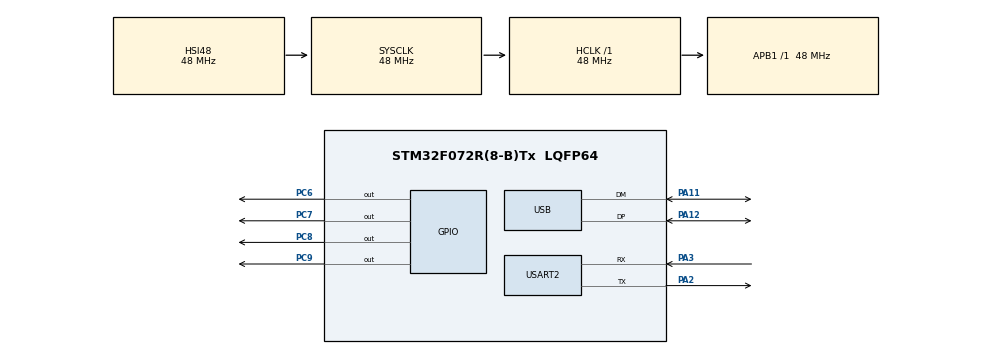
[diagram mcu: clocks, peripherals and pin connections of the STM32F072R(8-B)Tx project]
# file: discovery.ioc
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Dma.Request0=USART2_TX
Dma.USART2_TX.0.Direction=DMA_MEMORY_TO_PERIPH
Dma.USART2_TX.0.Instance=DMA1_Channel4
Dma.USART2_TX.0.MemDataAlignment=DMA_MDATAALIGN_BYTE
Dma.USART2_TX.0.MemInc=DMA_MINC_ENABLE
Dma.USART2_TX.0.Mode=DMA_NORMAL
Dma.USART2_TX.0.PeriphDataAlignment=DMA_PDATAALIGN_BYTE
Dma.USART2_TX.0.PeriphInc=DMA_PINC_DISABLE
Dma.USART2_TX.0.Priority=DMA_PRIORITY_LOW
Mcu.Family=STM32F0
Mcu.Name=STM32F072R(8-B)Tx
Mcu.Package=LQFP64
NVIC.DMA1_Channel4_5_6_7_IRQn=true\:0\:0\:false\:false\:true\:false
NVIC.TIM2_IRQn=true\:0\:0\:false\:false\:true\:true
NVIC.USB_IRQn=true\:0\:0\:false\:false\:true\:false
PA11.Mode=Device
PA11.Signal=USB_DM
PA12.Mode=Device
PA12.Signal=USB_DP
PA2.Mode=Asynchronous
PA2.Signal=USART2_TX
PA3.Mode=Asynchronous
PA3.Signal=USART2_RX
PC6.Signal=GPIO_Output
PC7.Signal=GPIO_Output
PC8.Signal=GPIO_Output
PC9.Signal=GPIO_Output
PF0-OSC_IN.Mode=HSE-External-Oscillator
PF0-OSC_IN.Signal=RCC_OSC_IN
PF1-OSC_OUT.Mode=HSE-External-Oscillator
PF1-OSC_OUT.Signal=RCC_OSC_OUT
ProjectManager.HeapSize=0x200
ProjectManager.StackSize=0x400
ProjectManager.TargetToolchain=MDK-ARM V5
RCC.AHBFreq_Value=48000000
RCC.APB1Freq_Value=48000000
RCC.APB1TimFreq_Value=48000000
RCC.HCLKFreq_Value=48000000
RCC.PLLSourceVirtual=RCC_PLLSOURCE_HSE
RCC.SYSCLKFreq_VALUE=48000000
RCC.SYSCLKSource=RCC_SYSCLKSOURCE_HSI48
RCC.USBFreq_Value=48000000
TIM2.TIM_MasterOutputTrigger=TIM_TRGO_UPDATE
USART2.AutoBaudRateEnableParam=UART_ADVFEATURE_AUTOBAUDRATE_ENABLE
USART2.VirtualMode-Asynchronous=VM_ASYNC
USART2.WordLength=WORDLENGTH_8B
USB.low_power_enable=DISABLE
USB_DEVICE.CLASS_NAME_FS=CUSTOMHID
USB_DEVICE.PID_CUSTOMHID_FS=1911
USB_DEVICE.PRODUCT_STRING_CUSTOMHID_FS=DiscoveryKEY
USB_DEVICE.VID=1638
USB_DEVICE.VirtualMode=CustomHid
USB_DEVICE.VirtualModeFS=Custom_Hid_FS
VP_TIM2_VS_ClockSourceINT.Mode=Internal
VP_USB_DEVICE_VS_USB_DEVICE_CUSTOM_HID_FS.Mode=CUSTOM_HID_FS
board=discovery

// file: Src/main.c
/**
  ******************************************************************************
  * File Name          : main.c
  * Description        : Main program body
  ******************************************************************************
  * This notice applies to any and all portions of this file
  * that are not between comment pairs USER CODE BEGIN and
  * USER CODE END. Other portions of this file, whether
  * inserted by the user or by software development tools
  * are owned by their respective copyright owners.
  *
  * Copyright (c) 2017 STMicroelectronics International N.V.
  * All rights reserved.
  *
  * Redistribution and use in source and binary forms, with or without
  * modification, are permitted, provided that the following conditions are met:
  *
  * 1. Redistribution of source code must retain the above copyright notice,
  *    this list of conditions and the following disclaimer.
  * 2. Redistributions in binary form must reproduce the above copyright notice,
  *    this list of conditions and the following disclaimer in the documentation
  *    and/or other materials provided with the distribution.
  * 3. Neither the name of STMicroelectronics nor the names of other
  *    contributors to this software may be used to endorse or promote products
  *    derived from this software without specific written permission.
  * 4. This software, including modifications and/or derivative works of this
  *    software, must execute solely and exclusively on microcontroller or
  *    microprocessor devices manufactured by or for STMicroelectronics.
  * 5. Redistribution and use of this software other than as permitted under
  *    this license is void and will automatically terminate your rights under
  *    this license.
  *
  * THIS SOFTWARE IS PROVIDED BY STMICROELECTRONICS AND CONTRIBUTORS "AS IS"
  * AND ANY EXPRESS, IMPLIED OR STATUTORY WARRANTIES, INCLUDING, BUT NOT
  * LIMITED TO, THE IMPLIED WARRANTIES OF MERCHANTABILITY, FITNESS FOR A
  * PARTICULAR PURPOSE AND NON-INFRINGEMENT OF THIRD PARTY INTELLECTUAL PROPERTY
  * RIGHTS ARE DISCLAIMED TO THE FULLEST EXTENT PERMITTED BY LAW. IN NO EVENT
  * SHALL STMICROELECTRONICS OR CONTRIBUTORS BE LIABLE FOR ANY DIRECT, INDIRECT,
  * INCIDENTAL, SPECIAL, EXEMPLARY, OR CONSEQUENTIAL DAMAGES (INCLUDING, BUT NOT
  * LIMITED TO, PROCUREMENT OF SUBSTITUTE GOODS OR SERVICES; LOSS OF USE, DATA,
  * OR PROFITS; OR BUSINESS INTERRUPTION) HOWEVER CAUSED AND ON ANY THEORY OF
  * LIABILITY, WHETHER IN CONTRACT, STRICT LIABILITY, OR TORT (INCLUDING
  * NEGLIGENCE OR OTHERWISE) ARISING IN ANY WAY OUT OF THE USE OF THIS SOFTWARE,
  * EVEN IF ADVISED OF THE POSSIBILITY OF SUCH DAMAGE.
  *
  ******************************************************************************
  */

#include "main.h"
#include "stm32f0xx_hal.h"
#include "usb_device.h"

/* USER CODE BEGIN Includes */
#include "usbd_customhid.h"
/* USER CODE END Includes */

TIM_HandleTypeDef htim2;

UART_HandleTypeDef huart2;
DMA_HandleTypeDef hdma_usart2_tx;

/* USER CODE BEGIN PV */
/* Private variables ---------------------------------------------------------*/

/* USER CODE END PV */

void SystemClock_Config(void);
static void MX_GPIO_Init(void);
static void MX_DMA_Init(void);
static void MX_USART2_UART_Init(void);
static void MX_TIM2_Init(void);

/* USER CODE BEGIN PFP */
/* Private function prototypes -----------------------------------------------*/

/* USER CODE END PFP */

int main(void)
{

  /* MCU Configuration----------------------------------------------------------*/

  /* Reset of all peripherals, Initializes the Flash interface and the Systick. */
  HAL_Init();

  /* Configure the system clock */
  SystemClock_Config();

  /* Initialize all configured peripherals */
  MX_GPIO_Init();
  MX_DMA_Init();
  MX_USB_DEVICE_Init();
  MX_USART2_UART_Init();
  MX_TIM2_Init();

	HAL_TIM_Base_Start_IT(&htim2);

  /* USER CODE BEGIN 2 */
	uint8_t dataToSend[65];
	dataToSend[0] = 1;
  dataToSend[1] = 2;
  dataToSend[2] = 3;
  dataToSend[3] = 4;
	dataToSend[4] = 5;

  /* USER CODE END 2 */

  /* Infinite loop */
  while (1)
  {
  /* USER CODE BEGIN 3 */
		HAL_Delay(100);
		//USBD_CUSTOM_HID_SendReport(&hUsbDeviceFS, dataToSend, 65);
  }
  /* USER CODE END 3 */

}

/** System Clock Configuration
*/
void SystemClock_Config(void)
{

  RCC_OscInitTypeDef RCC_OscInitStruct;
  RCC_ClkInitTypeDef RCC_ClkInitStruct;
  RCC_PeriphCLKInitTypeDef PeriphClkInit;

    /**Initializes the CPU, AHB and APB busses clocks
    */
  RCC_OscInitStruct.OscillatorType = RCC_OSCILLATORTYPE_HSI48;
  RCC_OscInitStruct.HSI48State = RCC_HSI48_ON;
  RCC_OscInitStruct.PLL.PLLState = RCC_PLL_NONE;
  if (HAL_RCC_OscConfig(&RCC_OscInitStruct) != HAL_OK)
  {
    _Error_Handler(__FILE__, __LINE__);
  }

    /**Initializes the CPU, AHB and APB busses clocks
    */
  RCC_ClkInitStruct.ClockType = RCC_CLOCKTYPE_HCLK|RCC_CLOCKTYPE_SYSCLK
                              |RCC_CLOCKTYPE_PCLK1;
  RCC_ClkInitStruct.SYSCLKSource = RCC_SYSCLKSOURCE_HSI48;
  RCC_ClkInitStruct.AHBCLKDivider = RCC_SYSCLK_DIV1;
  RCC_ClkInitStruct.APB1CLKDivider = RCC_HCLK_DIV1;

  if (HAL_RCC_ClockConfig(&RCC_ClkInitStruct, FLASH_LATENCY_1) != HAL_OK)
  {
    _Error_Handler(__FILE__, __LINE__);
  }

  PeriphClkInit.PeriphClockSelection = RCC_PERIPHCLK_USB|RCC_PERIPHCLK_USART2;
  PeriphClkInit.Usart2ClockSelection = RCC_USART2CLKSOURCE_PCLK1;
  PeriphClkInit.UsbClockSelection = RCC_USBCLKSOURCE_HSI48;

  if (HAL_RCCEx_PeriphCLKConfig(&PeriphClkInit) != HAL_OK)
  {
    _Error_Handler(__FILE__, __LINE__);
  }

    /**Configure the Systick interrupt time
    */
  HAL_SYSTICK_Config(HAL_RCC_GetHCLKFreq()/1000);

    /**Configure the Systick
    */
  HAL_SYSTICK_CLKSourceConfig(SYSTICK_CLKSOURCE_HCLK);

  /* SysTick_IRQn interrupt configuration */
  HAL_NVIC_SetPriority(SysTick_IRQn, 0, 0);
}

/* TIM2 init function */
static void MX_TIM2_Init(void)
{

  TIM_ClockConfigTypeDef sClockSourceConfig;
  TIM_MasterConfigTypeDef sMasterConfig;

  htim2.Instance = TIM2;
  htim2.Init.Prescaler =47999;
  htim2.Init.CounterMode = TIM_COUNTERMODE_UP;
  htim2.Init.Period = 499;
  htim2.Init.ClockDivision = TIM_CLOCKDIVISION_DIV1;
  htim2.Init.AutoReloadPreload = TIM_AUTORELOAD_PRELOAD_DISABLE;
  if (HAL_TIM_Base_Init(&htim2) != HAL_OK)
  {
    _Error_Handler(__FILE__, __LINE__);
  }

  sClockSourceConfig.ClockSource = TIM_CLOCKSOURCE_INTERNAL;
  if (HAL_TIM_ConfigClockSource(&htim2, &sClockSourceConfig) != HAL_OK)
  {
    _Error_Handler(__FILE__, __LINE__);
  }

  sMasterConfig.MasterOutputTrigger = TIM_TRGO_UPDATE;
  sMasterConfig.MasterSlaveMode = TIM_MASTERSLAVEMODE_DISABLE;
  if (HAL_TIMEx_MasterConfigSynchronization(&htim2, &sMasterConfig) != HAL_OK)
  {
    _Error_Handler(__FILE__, __LINE__);
  }

}

/* USART2 init function */
static void MX_USART2_UART_Init(void)
{

  huart2.Instance = USART2;
  huart2.Init.BaudRate = 38400;
  huart2.Init.WordLength = UART_WORDLENGTH_8B;
  huart2.Init.StopBits = UART_STOPBITS_1;
  huart2.Init.Parity = UART_PARITY_NONE;
  huart2.Init.Mode = UART_MODE_TX_RX;
  huart2.Init.HwFlowCtl = UART_HWCONTROL_NONE;
  huart2.Init.OverSampling = UART_OVERSAMPLING_16;
  huart2.Init.OneBitSampling = UART_ONE_BIT_SAMPLE_DISABLE;
  huart2.AdvancedInit.AdvFeatureInit = UART_ADVFEATURE_AUTOBAUDRATE_INIT;
  huart2.AdvancedInit.AutoBaudRateEnable = UART_ADVFEATURE_AUTOBAUDRATE_ENABLE;
  huart2.AdvancedInit.AutoBaudRateMode = UART_ADVFEATURE_AUTOBAUDRATE_ONSTARTBIT;
  if (HAL_UART_Init(&huart2) != HAL_OK)
  {
    _Error_Handler(__FILE__, __LINE__);
  }

}

static void MX_DMA_Init(void)
{
  /* DMA controller clock enable */
  __HAL_RCC_DMA1_CLK_ENABLE();

  /* DMA interrupt init */
  /* DMA1_Channel4_5_6_7_IRQn interrupt configuration */
  HAL_NVIC_SetPriority(DMA1_Channel4_5_6_7_IRQn, 0, 0);
  HAL_NVIC_EnableIRQ(DMA1_Channel4_5_6_7_IRQn);

}

/** Configure pins as
        * Analog
        * Input
        * Output
        * EVENT_OUT
        * EXTI
*/
static void MX_GPIO_Init(void)
{

  GPIO_InitTypeDef GPIO_InitStruct;

  /* GPIO Ports Clock Enable */
  __HAL_RCC_GPIOF_CLK_ENABLE();
  __HAL_RCC_GPIOA_CLK_ENABLE();
  __HAL_RCC_GPIOC_CLK_ENABLE();

  /*Configure GPIO pin Output Level */
  HAL_GPIO_WritePin(GPIOC, GPIO_PIN_6|GPIO_PIN_7|GPIO_PIN_8|GPIO_PIN_9, GPIO_PIN_RESET);

  /*Configure GPIO pins : PC6 PC7 PC8 PC9 */
  GPIO_InitStruct.Pin = GPIO_PIN_6|GPIO_PIN_7|GPIO_PIN_8|GPIO_PIN_9;
  GPIO_InitStruct.Mode = GPIO_MODE_OUTPUT_PP;
  GPIO_InitStruct.Pull = GPIO_NOPULL;
  GPIO_InitStruct.Speed = GPIO_SPEED_FREQ_LOW;
  HAL_GPIO_Init(GPIOC, &GPIO_InitStruct);

}

void _Error_Handler(char * file, int line)
{
  while(1)
  {
  }
}

/************************ (C) COPYRIGHT STMicroelectronics *****END OF FILE****/
